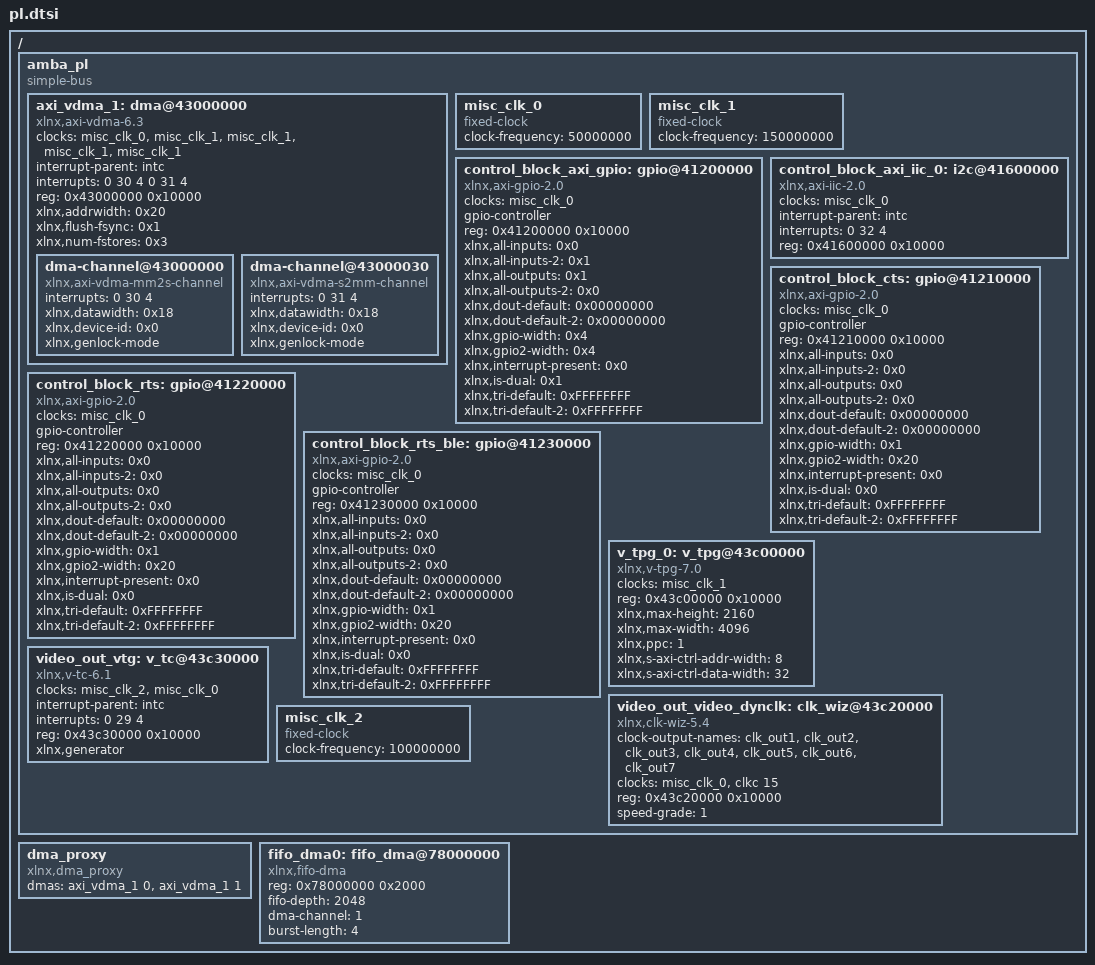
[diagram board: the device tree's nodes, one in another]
/*
 * CAUTION: This file is automatically generated by Xilinx.
 * Version: HSI 2017.4
 * Today is: Thu Jun  6 17:20:53 2019
 */


/ {
	amba_pl: amba_pl {
		#address-cells = <1>;
		#size-cells = <1>;
		compatible = "simple-bus";
		ranges ;
		axi_vdma_1: dma@43000000 {
			#dma-cells = <1>;
			clock-names = "s_axi_lite_aclk", "m_axi_mm2s_aclk", "m_axis_mm2s_aclk", "m_axi_s2mm_aclk", "s_axis_s2mm_aclk";
			clocks = <&misc_clk_0>, <&misc_clk_1>, <&misc_clk_1>, <&misc_clk_1>, <&misc_clk_1>;
			compatible = "xlnx,axi-vdma-6.3", "xlnx,axi-vdma-1.00.a";
			interrupt-names = "mm2s_introut", "s2mm_introut";
			interrupt-parent = <&intc>;
			interrupts = <0 30 4 0 31 4>;
			reg = <0x43000000 0x10000>;
			xlnx,addrwidth = <0x20>;
			xlnx,flush-fsync = <0x1>;
			xlnx,num-fstores = <0x3>;
			dma-channel@43000000 {
				compatible = "xlnx,axi-vdma-mm2s-channel";
				interrupts = <0 30 4>;
				xlnx,datawidth = <0x18>;
				xlnx,device-id = <0x0>;
				xlnx,genlock-mode ;
			};
			dma-channel@43000030 {
				compatible = "xlnx,axi-vdma-s2mm-channel";
				interrupts = <0 31 4>;
				xlnx,datawidth = <0x18>;
				xlnx,device-id = <0x0>;
				xlnx,genlock-mode ;
			};
		};
		misc_clk_0: misc_clk_0 {
			#clock-cells = <0>;
			clock-frequency = <50000000>;
			compatible = "fixed-clock";
		};
		misc_clk_1: misc_clk_1 {
			#clock-cells = <0>;
			clock-frequency = <150000000>;
			compatible = "fixed-clock";
		};
		control_block_axi_gpio: gpio@41200000 {
			#gpio-cells = <3>;
			clock-names = "s_axi_aclk";
			clocks = <&misc_clk_0>;
			compatible = "xlnx,axi-gpio-2.0", "xlnx,xps-gpio-1.00.a";
			gpio-controller ;
			reg = <0x41200000 0x10000>;
			xlnx,all-inputs = <0x0>;
			xlnx,all-inputs-2 = <0x1>;
			xlnx,all-outputs = <0x1>;
			xlnx,all-outputs-2 = <0x0>;
			xlnx,dout-default = <0x00000000>;
			xlnx,dout-default-2 = <0x00000000>;
			xlnx,gpio-width = <0x4>;
			xlnx,gpio2-width = <0x4>;
			xlnx,interrupt-present = <0x0>;
			xlnx,is-dual = <0x1>;
			xlnx,tri-default = <0xFFFFFFFF>;
			xlnx,tri-default-2 = <0xFFFFFFFF>;
		};
		control_block_axi_iic_0: i2c@41600000 {
			#address-cells = <1>;
			#size-cells = <0>;
			clock-names = "s_axi_aclk";
			clocks = <&misc_clk_0>;
			compatible = "xlnx,axi-iic-2.0", "xlnx,xps-iic-2.00.a";
			interrupt-names = "iic2intc_irpt";
			interrupt-parent = <&intc>;
			interrupts = <0 32 4>;
			reg = <0x41600000 0x10000>;
		};
		control_block_cts: gpio@41210000 {
			#gpio-cells = <3>;
			clock-names = "s_axi_aclk";
			clocks = <&misc_clk_0>;
			compatible = "xlnx,axi-gpio-2.0", "xlnx,xps-gpio-1.00.a";
			gpio-controller ;
			reg = <0x41210000 0x10000>;
			xlnx,all-inputs = <0x0>;
			xlnx,all-inputs-2 = <0x0>;
			xlnx,all-outputs = <0x0>;
			xlnx,all-outputs-2 = <0x0>;
			xlnx,dout-default = <0x00000000>;
			xlnx,dout-default-2 = <0x00000000>;
			xlnx,gpio-width = <0x1>;
			xlnx,gpio2-width = <0x20>;
			xlnx,interrupt-present = <0x0>;
			xlnx,is-dual = <0x0>;
			xlnx,tri-default = <0xFFFFFFFF>;
			xlnx,tri-default-2 = <0xFFFFFFFF>;
		};
		control_block_rts: gpio@41220000 {
			#gpio-cells = <3>;
			clock-names = "s_axi_aclk";
			clocks = <&misc_clk_0>;
			compatible = "xlnx,axi-gpio-2.0", "xlnx,xps-gpio-1.00.a";
			gpio-controller ;
			reg = <0x41220000 0x10000>;
			xlnx,all-inputs = <0x0>;
			xlnx,all-inputs-2 = <0x0>;
			xlnx,all-outputs = <0x0>;
			xlnx,all-outputs-2 = <0x0>;
			xlnx,dout-default = <0x00000000>;
			xlnx,dout-default-2 = <0x00000000>;
			xlnx,gpio-width = <0x1>;
			xlnx,gpio2-width = <0x20>;
			xlnx,interrupt-present = <0x0>;
			xlnx,is-dual = <0x0>;
			xlnx,tri-default = <0xFFFFFFFF>;
			xlnx,tri-default-2 = <0xFFFFFFFF>;
		};
		control_block_rts_ble: gpio@41230000 {
			#gpio-cells = <3>;
			clock-names = "s_axi_aclk";
			clocks = <&misc_clk_0>;
			compatible = "xlnx,axi-gpio-2.0", "xlnx,xps-gpio-1.00.a";
			gpio-controller ;
			reg = <0x41230000 0x10000>;
			xlnx,all-inputs = <0x0>;
			xlnx,all-inputs-2 = <0x0>;
			xlnx,all-outputs = <0x0>;
			xlnx,all-outputs-2 = <0x0>;
			xlnx,dout-default = <0x00000000>;
			xlnx,dout-default-2 = <0x00000000>;
			xlnx,gpio-width = <0x1>;
			xlnx,gpio2-width = <0x20>;
			xlnx,interrupt-present = <0x0>;
			xlnx,is-dual = <0x0>;
			xlnx,tri-default = <0xFFFFFFFF>;
			xlnx,tri-default-2 = <0xFFFFFFFF>;
		};
		v_tpg_0: v_tpg@43c00000 {
			clock-names = "ap_clk";
			clocks = <&misc_clk_1>;
			compatible = "xlnx,v-tpg-7.0", "xlnx,v-tpg-7.0, generic-uio";
			reg = <0x43c00000 0x10000>;
			xlnx,max-height = <2160>;
			xlnx,max-width = <4096>;
			xlnx,ppc = <1>;
			xlnx,s-axi-ctrl-addr-width = <8>;
			xlnx,s-axi-ctrl-data-width = <32>;
		};
		video_out_video_dynclk: clk_wiz@43c20000 {
			#clock-cells = <1>;
			clock-names = "s_axi_aclk", "clk_in1";
			clock-output-names = "clk_out1", "clk_out2", "clk_out3", "clk_out4", "clk_out5", "clk_out6", "clk_out7";
			clocks = <&misc_clk_0>, <&clkc 15>;
			compatible = "xlnx,clk-wiz-5.4", "xlnx,clocking-wizard";
			reg = <0x43c20000 0x10000>;
			speed-grade = <1>;
		};
		video_out_vtg: v_tc@43c30000 {
			clock-names = "clk", "s_axi_aclk";
			clocks = <&misc_clk_2>, <&misc_clk_0>;
			compatible = "xlnx,v-tc-6.1", "xlnx,v-tc-6.1";
			interrupt-names = "irq";
			interrupt-parent = <&intc>;
			interrupts = <0 29 4>;
			reg = <0x43c30000 0x10000>;
			xlnx,generator ;
		};
		misc_clk_2: misc_clk_2 {
			#clock-cells = <0>;
			clock-frequency = <100000000>;
			compatible = "fixed-clock";
		};

	};
	dma_proxy {
		compatible ="xlnx,dma_proxy";
		dmas = <&axi_vdma_1 0
			&axi_vdma_1 1>;
		dma-names = "dma_proxy_tx", "dma_proxy_rx";
	};
	fifo_dma0: fifo_dma@78000000 {
	    compatible = "xlnx,fifo-dma";
	    reg = <0x78000000 0x2000>;
	    fifo-depth = <2048>;
	    dma-channel = <1>;
	    burst-length = <4>;
	};
};
